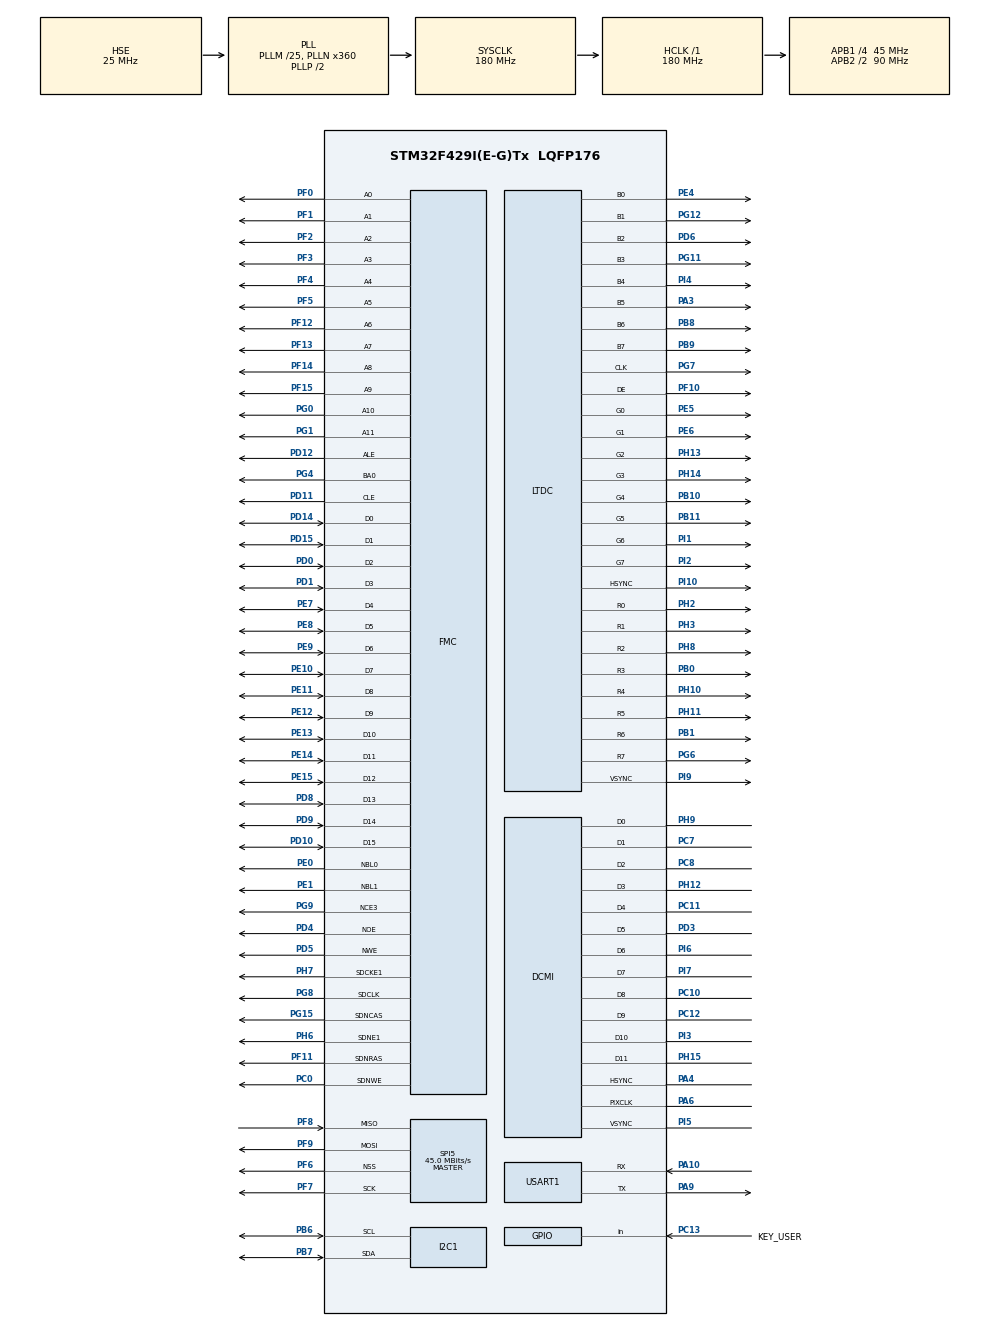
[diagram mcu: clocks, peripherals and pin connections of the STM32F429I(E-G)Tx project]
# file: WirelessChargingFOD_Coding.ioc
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ARM.CMSIS.5.6.0.CMSISJjCORE=true
ARM.CMSIS.5.6.0.CMSISJjDSP=Library
Mcu.Family=STM32F4
Mcu.Name=STM32F429I(E-G)Tx
Mcu.Package=LQFP176
NVIC.PriorityGroup=NVIC_PRIORITYGROUP_4
PA0/WKUP.Mode=SYS_WakeUp0
PA0/WKUP.Signal=SYS_WKUP
PA10.Mode=Asynchronous
PA10.Signal=USART1_RX
PA13.Mode=Serial_Wire
PA13.Signal=SYS_JTMS-SWDIO
PA14.Mode=Serial_Wire
PA14.Signal=SYS_JTCK-SWCLK
PA3.Mode=RGB888
PA3.Signal=LTDC_B5
PA4.Mode=Slave_12_bits_External_Synchro
PA4.Signal=DCMI_HSYNC
PA6.Mode=Slave_12_bits_External_Synchro
PA6.Signal=DCMI_PIXCLK
PA9.Mode=Asynchronous
PA9.Signal=USART1_TX
PB0.Mode=RGB888
PB0.Signal=LTDC_R3
PB1.Mode=RGB888
PB1.Signal=LTDC_R6
PB10.Mode=RGB888
PB10.Signal=LTDC_G4
PB11.Mode=RGB888
PB11.Signal=LTDC_G5
PB6.Mode=I2C
PB6.Signal=I2C1_SCL
PB7.Mode=I2C
PB7.Signal=I2C1_SDA
PB8.Mode=RGB888
PB8.Signal=LTDC_B6
PB9.Mode=RGB888
PB9.Signal=LTDC_B7
PC0.Signal=FMC_SDNWE
PC10.Mode=Slave_12_bits_External_Synchro
PC10.Signal=DCMI_D8
PC11.Mode=Slave_12_bits_External_Synchro
PC11.Signal=DCMI_D4
PC12.Mode=Slave_12_bits_External_Synchro
PC12.Signal=DCMI_D9
PC13.GPIO_Label=KEY_USER
PC13.Signal=GPIO_Input
PC14/OSC32_IN.Mode=LSE-External-Oscillator
PC14/OSC32_IN.Signal=RCC_OSC32_IN
PC15/OSC32_OUT.Mode=LSE-External-Oscillator
PC15/OSC32_OUT.Signal=RCC_OSC32_OUT
PC7.Mode=Slave_12_bits_External_Synchro
PC7.Signal=DCMI_D1
PC8.Mode=Slave_12_bits_External_Synchro
PC8.Signal=DCMI_D2
PD0.Signal=FMC_D2_DA2
PD1.Signal=FMC_D3_DA3
PD10.Signal=FMC_D15_DA15
PD11.Signal=FMC_A16_CLE
PD12.Signal=FMC_A17_ALE
PD14.Signal=FMC_D0_DA0
PD15.Signal=FMC_D1_DA1
PD3.Mode=Slave_12_bits_External_Synchro
PD3.Signal=DCMI_D5
PD4.Signal=FMC_NOE
PD5.Signal=FMC_NWE
PD6.Mode=RGB888
PD6.Signal=LTDC_B2
PD8.Signal=FMC_D13_DA13
PD9.Signal=FMC_D14_DA14
PE0.Signal=FMC_NBL0
PE1.Signal=FMC_NBL1
PE10.Signal=FMC_D7_DA7
PE11.Signal=FMC_D8_DA8
PE12.Signal=FMC_D9_DA9
PE13.Signal=FMC_D10_DA10
PE14.Signal=FMC_D11_DA11
PE15.Signal=FMC_D12_DA12
PE4.Mode=RGB888
PE4.Signal=LTDC_B0
PE5.Mode=RGB888
PE5.Signal=LTDC_G0
PE6.Mode=RGB888
PE6.Signal=LTDC_G1
PE7.Signal=FMC_D4_DA4
PE8.Signal=FMC_D5_DA5
PE9.Signal=FMC_D6_DA6
PF0.Signal=FMC_A0
PF1.Signal=FMC_A1
PF10.Mode=RGB888
PF10.Signal=LTDC_DE
PF11.Signal=FMC_SDNRAS
PF12.Signal=FMC_A6
PF13.Signal=FMC_A7
PF14.Signal=FMC_A8
PF15.Signal=FMC_A9
PF2.Signal=FMC_A2
PF3.Signal=FMC_A3
PF4.Signal=FMC_A4
PF5.Signal=FMC_A5
PF6.Mode=NSS_Signal_Hard_Output
PF6.Signal=SPI5_NSS
PF7.Mode=Full_Duplex_Master
PF7.Signal=SPI5_SCK
PF8.Mode=Full_Duplex_Master
PF8.Signal=SPI5_MISO
PF9.Mode=Full_Duplex_Master
PF9.Signal=SPI5_MOSI
PG0.Signal=FMC_A10
PG1.Signal=FMC_A11
PG11.Mode=RGB888
PG11.Signal=LTDC_B3
PG12.Mode=RGB888
PG12.Signal=LTDC_B1
PG15.Signal=FMC_SDNCAS
PG4.Signal=FMC_A14_BA0
PG6.Mode=RGB888
PG6.Signal=LTDC_R7
PG7.Mode=RGB888
PG7.Signal=LTDC_CLK
PG8.Signal=FMC_SDCLK
PG9.Mode=NandChipSelect3_1
PG9.Signal=FMC_NCE3
PH0/OSC_IN.Mode=HSE-External-Oscillator
PH0/OSC_IN.Signal=RCC_OSC_IN
PH1/OSC_OUT.Mode=HSE-External-Oscillator
PH1/OSC_OUT.Signal=RCC_OSC_OUT
PH10.Mode=RGB888
PH10.Signal=LTDC_R4
PH11.Mode=RGB888
PH11.Signal=LTDC_R5
PH12.Mode=Slave_12_bits_External_Synchro
PH12.Signal=DCMI_D3
PH13.Mode=RGB888
PH13.Signal=LTDC_G2
PH14.Mode=RGB888
PH14.Signal=LTDC_G3
PH15.Mode=Slave_12_bits_External_Synchro
PH15.Signal=DCMI_D11
PH2.Mode=RGB888
PH2.Signal=LTDC_R0
PH3.Mode=RGB888
PH3.Signal=LTDC_R1
PH6.Mode=SdramChipSelect2_1
PH6.Signal=FMC_SDNE1
PH7.Mode=SdramChipSelect2_1
PH7.Signal=FMC_SDCKE1
PH8.Mode=RGB888
PH8.Signal=LTDC_R2
PH9.Mode=Slave_12_bits_External_Synchro
PH9.Signal=DCMI_D0
PI1.Mode=RGB888
PI1.Signal=LTDC_G6
PI10.Mode=RGB888
PI10.Signal=LTDC_HSYNC
PI2.Mode=RGB888
PI2.Signal=LTDC_G7
PI3.Mode=Slave_12_bits_External_Synchro
PI3.Signal=DCMI_D10
PI4.Mode=RGB888
PI4.Signal=LTDC_B4
PI5.Mode=Slave_12_bits_External_Synchro
PI5.Signal=DCMI_VSYNC
PI6.Mode=Slave_12_bits_External_Synchro
PI6.Signal=DCMI_D6
PI7.Mode=Slave_12_bits_External_Synchro
PI7.Signal=DCMI_D7
PI9.Mode=RGB888
PI9.Signal=LTDC_VSYNC
ProjectManager.HeapSize=0x200
ProjectManager.StackSize=0x400
ProjectManager.TargetToolchain=STM32CubeIDE
RCC.48MHZClocksFreq_Value=90000000
RCC.AHBFreq_Value=180000000
RCC.APB1CLKDivider=RCC_HCLK_DIV4
RCC.APB1Freq_Value=45000000
RCC.APB1TimFreq_Value=90000000
RCC.APB2CLKDivider=RCC_HCLK_DIV2
RCC.APB2Freq_Value=90000000
RCC.APB2TimFreq_Value=180000000
RCC.CortexFreq_Value=180000000
RCC.HCLKFreq_Value=180000000
RCC.HSE_VALUE=25000000
RCC.HSI_VALUE=16000000
RCC.PLLM=25
RCC.PLLN=360
RCC.PLLSAIN=360
RCC.PLLSourceVirtual=RCC_PLLSOURCE_HSE
RCC.SYSCLKFreq_VALUE=180000000
RCC.SYSCLKSource=RCC_SYSCLKSOURCE_PLLCLK
RCC.VCOOutputFreq_Value=360000000
RTC.Format=RTC_FORMAT_BIN
SH.FMC_A0.0=FMC_A0,12b-sda1
SH.FMC_A1.0=FMC_A1,12b-sda1
SH.FMC_A10.0=FMC_A10,12b-sda1
SH.FMC_A11.0=FMC_A11,12b-sda1
SH.FMC_A14_BA0.0=FMC_BA0,TwoSdramBanks1
SH.FMC_A16_CLE.0=FMC_CLE,8b-dmux1
SH.FMC_A17_ALE.0=FMC_ALE,8b-dmux1
SH.FMC_A2.0=FMC_A2,12b-sda1
SH.FMC_A3.0=FMC_A3,12b-sda1
SH.FMC_A4.0=FMC_A4,12b-sda1
SH.FMC_A5.0=FMC_A5,12b-sda1
SH.FMC_A6.0=FMC_A6,12b-sda1
SH.FMC_A7.0=FMC_A7,12b-sda1
SH.FMC_A8.0=FMC_A8,12b-sda1
SH.FMC_A9.0=FMC_A9,12b-sda1
SH.FMC_D0_DA0.0=FMC_D0,sd-16b-d1
SH.FMC_D0_DA0.1=FMC_D0,8b-dmux1
SH.FMC_D10_DA10.0=FMC_D10,sd-16b-d1
SH.FMC_D11_DA11.0=FMC_D11,sd-16b-d1
SH.FMC_D12_DA12.0=FMC_D12,sd-16b-d1
SH.FMC_D13_DA13.0=FMC_D13,sd-16b-d1
SH.FMC_D14_DA14.0=FMC_D14,sd-16b-d1
SH.FMC_D15_DA15.0=FMC_D15,sd-16b-d1
SH.FMC_D1_DA1.0=FMC_D1,sd-16b-d1
SH.FMC_D1_DA1.1=FMC_D1,8b-dmux1
SH.FMC_D2_DA2.0=FMC_D2,sd-16b-d1
SH.FMC_D2_DA2.1=FMC_D2,8b-dmux1
SH.FMC_D3_DA3.0=FMC_D3,sd-16b-d1
SH.FMC_D3_DA3.1=FMC_D3,8b-dmux1
SH.FMC_D4_DA4.0=FMC_D4,sd-16b-d1
SH.FMC_D4_DA4.1=FMC_D4,8b-dmux1
SH.FMC_D5_DA5.0=FMC_D5,sd-16b-d1
SH.FMC_D5_DA5.1=FMC_D5,8b-dmux1
SH.FMC_D6_DA6.0=FMC_D6,sd-16b-d1
SH.FMC_D6_DA6.1=FMC_D6,8b-dmux1
SH.FMC_D7_DA7.0=FMC_D7,sd-16b-d1
SH.FMC_D7_DA7.1=FMC_D7,8b-dmux1
SH.FMC_D8_DA8.0=FMC_D8,sd-16b-d1
SH.FMC_D9_DA9.0=FMC_D9,sd-16b-d1
SH.FMC_NBL0.0=FMC_NBL0,Sd2ByteEnable1
SH.FMC_NBL1.0=FMC_NBL1,Sd2ByteEnable1
SH.FMC_NOE.0=FMC_NOE,8b-dmux1
SH.FMC_NWE.0=FMC_NWE,8b-dmux1
SH.FMC_SDCLK.0=FMC_SDCLK,12b-sda1
SH.FMC_SDNCAS.0=FMC_SDNCAS,12b-sda1
SH.FMC_SDNRAS.0=FMC_SDNRAS,12b-sda1
SH.FMC_SDNWE.0=FMC_SDNWE,12b-sda1
SPI5.CalculateBaudRate=45.0 MBits/s
SPI5.Direction=SPI_DIRECTION_2LINES
SPI5.Mode=SPI_MODE_MASTER
SPI5.VirtualNSS=VM_NSSHARD
SPI5.VirtualType=VM_MASTER
USART1.VirtualMode=VM_ASYNC
VP_ARM.CMSIS_VS_CMSISJjCORE_5.3.0.Mode=CMSISJjCORE
VP_ARM.CMSIS_VS_CMSISJjDSP_1.7.0.Mode=CMSISJjDSP
VP_RTC_VS_RTC_Activate.Mode=RTC_Enabled
VP_RTC_VS_RTC_Calendar.Mode=RTC_Calendar
board=custom

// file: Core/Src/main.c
/* USER CODE BEGIN Header */
/**
  ******************************************************************************
  * @file           : main.c
  * @brief          : Main program body
  ******************************************************************************
  * @attention
  *
  * <h2><center>&copy; Copyright (c) 2020 STMicroelectronics.
  * All rights reserved.</center></h2>
  *
  * This software component is licensed by ST under BSD 3-Clause license,
  * the "License"; You may not use this file except in compliance with the
  * License. You may obtain a copy of the License at:
  *                        opensource.org/licenses/BSD-3-Clause
  *
  ******************************************************************************
  */
/* USER CODE END Header */

#include <drv_adg1439.hpp>
#include "main.h"
#include "dcmi.h"
#include "i2c.h"
#include "ltdc.h"
#include "rtc.h"
#include "spi.h"
#include "usart.h"
#include "gpio.h"
#include "fmc.h"

/* USER CODE BEGIN Includes */
#include "arm_math.h"
#include "inc_stdlib.hpp"
#include "drv_adg1439.hpp"

/* USER CODE END Includes */

void SystemClock_Config(void);

int main(void)
{

  /* MCU Configuration--------------------------------------------------------*/

  /* Reset of all peripherals, Initializes the Flash interface and the Systick. */
  HAL_Init();

  /* Configure the system clock */
  SystemClock_Config();

  /* Initialize all configured peripherals */
  MX_GPIO_Init();
  MX_FMC_Init();
  MX_I2C1_Init();
  MX_LTDC_Init();
  MX_SPI5_Init();
  MX_USART1_UART_Init();
  MX_DCMI_Init();
  MX_RTC_Init();
  /* USER CODE BEGIN 2 */
  ADG1439_PORT_delay_ms(1);
  /* USER CODE END 2 */

  /* Infinite loop */
  while (1)
  {

  }
}

void SystemClock_Config(void)
{
  RCC_OscInitTypeDef RCC_OscInitStruct = {0};
  RCC_ClkInitTypeDef RCC_ClkInitStruct = {0};
  RCC_PeriphCLKInitTypeDef PeriphClkInitStruct = {0};

  /** Configure the main internal regulator output voltage
  */
  __HAL_RCC_PWR_CLK_ENABLE();
  __HAL_PWR_VOLTAGESCALING_CONFIG(PWR_REGULATOR_VOLTAGE_SCALE1);
  /** Initializes the CPU, AHB and APB busses clocks
  */
  RCC_OscInitStruct.OscillatorType = RCC_OSCILLATORTYPE_LSI|RCC_OSCILLATORTYPE_HSE;
  RCC_OscInitStruct.HSEState = RCC_HSE_ON;
  RCC_OscInitStruct.LSIState = RCC_LSI_ON;
  RCC_OscInitStruct.PLL.PLLState = RCC_PLL_ON;
  RCC_OscInitStruct.PLL.PLLSource = RCC_PLLSOURCE_HSE;
  RCC_OscInitStruct.PLL.PLLM = 25;
  RCC_OscInitStruct.PLL.PLLN = 360;
  RCC_OscInitStruct.PLL.PLLP = RCC_PLLP_DIV2;
  RCC_OscInitStruct.PLL.PLLQ = 4;
  if (HAL_RCC_OscConfig(&RCC_OscInitStruct) != HAL_OK)
  {
    Error_Handler();
  }
  /** Activate the Over-Drive mode
  */
  if (HAL_PWREx_EnableOverDrive() != HAL_OK)
  {
    Error_Handler();
  }
  /** Initializes the CPU, AHB and APB busses clocks
  */
  RCC_ClkInitStruct.ClockType = RCC_CLOCKTYPE_HCLK|RCC_CLOCKTYPE_SYSCLK
                              |RCC_CLOCKTYPE_PCLK1|RCC_CLOCKTYPE_PCLK2;
  RCC_ClkInitStruct.SYSCLKSource = RCC_SYSCLKSOURCE_PLLCLK;
  RCC_ClkInitStruct.AHBCLKDivider = RCC_SYSCLK_DIV1;
  RCC_ClkInitStruct.APB1CLKDivider = RCC_HCLK_DIV4;
  RCC_ClkInitStruct.APB2CLKDivider = RCC_HCLK_DIV2;

  if (HAL_RCC_ClockConfig(&RCC_ClkInitStruct, FLASH_LATENCY_5) != HAL_OK)
  {
    Error_Handler();
  }
  PeriphClkInitStruct.PeriphClockSelection = RCC_PERIPHCLK_LTDC|RCC_PERIPHCLK_RTC;
  PeriphClkInitStruct.PLLSAI.PLLSAIN = 360;
  PeriphClkInitStruct.PLLSAI.PLLSAIR = 2;
  PeriphClkInitStruct.PLLSAIDivR = RCC_PLLSAIDIVR_2;
  PeriphClkInitStruct.RTCClockSelection = RCC_RTCCLKSOURCE_LSI;
  if (HAL_RCCEx_PeriphCLKConfig(&PeriphClkInitStruct) != HAL_OK)
  {
    Error_Handler();
  }
}

void Error_Handler(void)
{
}

/************************ (C) COPYRIGHT STMicroelectronics *****END OF FILE****/
